AUTOSAR XML (schema 4-2-2)
package /ComponentTypes
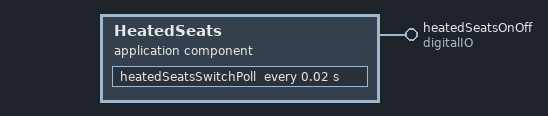
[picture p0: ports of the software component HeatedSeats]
  application sw component type HeatedSeats
    provide port heatedSeatsOnOff: nonqueued-sender-com-spec{data-element=boolean, init-value=0}, provided-interface=digitalIO
    behavior HeatedSeats_InternalBehavior
      timing event TMT_heatedSeatsSwitchPoll: start-on-event=heatedSeatsSwitchPoll, period=0.02
      runnable heatedSeatsSwitchPoll
        data-send-points:
          access SEND_heatedSeatsOnOff_boolean: accessed-variable=heatedSeatsOnOff.boolean
  swc implementation HeatedSeats_Implementation: behavior=HeatedSeats_InternalBehavior
